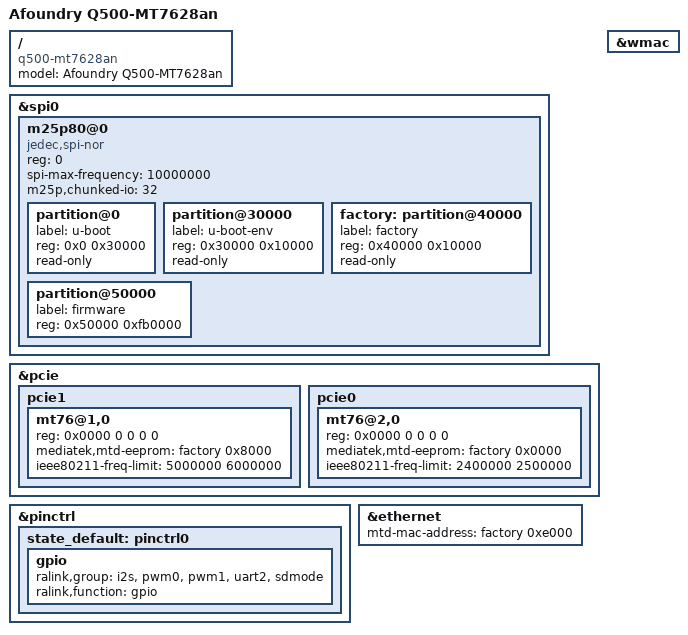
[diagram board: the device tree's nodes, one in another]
/dts-v1/;

#include "mt7628an.dtsi"

#include <dt-bindings/gpio/gpio.h>
#include <dt-bindings/input/input.h>

/ {
	compatible = "q500-mt7628an", "mt7628", "mediatek,mt7628an-soc";
	model = "Afoundry Q500-MT7628an";
	};

&spi0 {
	status = "okay";

	m25p80@0 {
		#address-cells = <1>;
		#size-cells = <1>;
		compatible = "jedec,spi-nor";
		reg = <0>;
		spi-max-frequency = <10000000>;
		m25p,chunked-io = <32>;

		partition@0 {
			label = "u-boot";
			reg = <0x0 0x30000>;
			read-only;
		};

		partition@30000 {
			label = "u-boot-env";
			reg = <0x30000 0x10000>;
			read-only;
		};

		factory: partition@40000 {
			label = "factory";
			reg = <0x40000 0x10000>;
			read-only;
		};

		partition@50000 {
			label = "firmware";
			reg = <0x50000 0xfb0000>;
		};
	};
};

&pcie {
	status = "okay";

	pcie1 {
		mt76@1,0 {
			reg = <0x0000 0 0 0 0>;
			device_type = "pci";
			mediatek,mtd-eeprom = <&factory 0x8000>;
			ieee80211-freq-limit = <5000000 6000000>;
		};
	};

	pcie0 {
		mt76@2,0 {
			reg = <0x0000 0 0 0 0>;
			device_type = "pci";
			mediatek,mtd-eeprom = <&factory 0x0000>;
			ieee80211-freq-limit = <2400000 2500000>;
		};
	};
};

&pinctrl {
    state_default: pinctrl0 {
        gpio {
            ralink,group = "i2s", "pwm0", "pwm1", "uart2", "sdmode";
            ralink,function = "gpio";
        };
    };
};

&wmac {
	status = "okay";
};

&ethernet {
	mtd-mac-address = <&factory 0xe000>;
};
